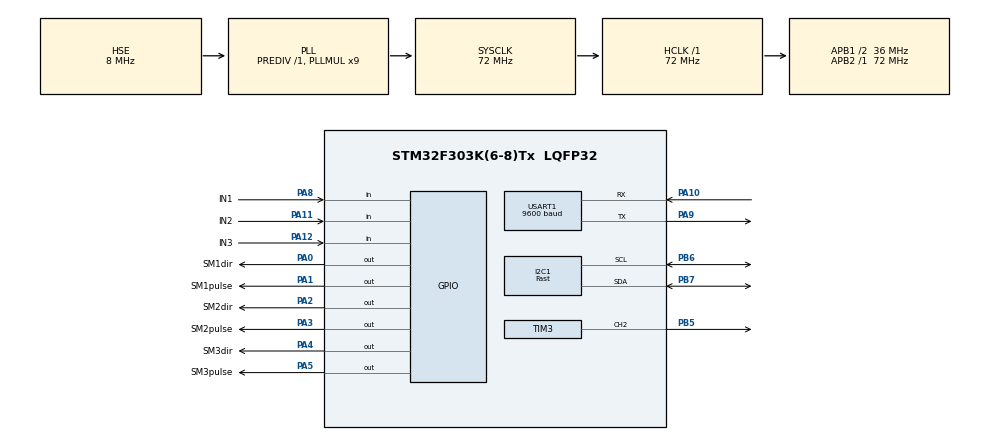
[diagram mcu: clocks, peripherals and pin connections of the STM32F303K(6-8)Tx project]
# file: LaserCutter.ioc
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Dma.I2C1_RX.1.Direction=DMA_PERIPH_TO_MEMORY
Dma.I2C1_RX.1.Instance=DMA1_Channel7
Dma.I2C1_RX.1.MemDataAlignment=DMA_MDATAALIGN_BYTE
Dma.I2C1_RX.1.MemInc=DMA_MINC_ENABLE
Dma.I2C1_RX.1.Mode=DMA_NORMAL
Dma.I2C1_RX.1.PeriphDataAlignment=DMA_PDATAALIGN_BYTE
Dma.I2C1_RX.1.PeriphInc=DMA_PINC_DISABLE
Dma.I2C1_RX.1.Priority=DMA_PRIORITY_LOW
Dma.I2C1_TX.0.Direction=DMA_MEMORY_TO_PERIPH
Dma.I2C1_TX.0.Instance=DMA1_Channel6
Dma.I2C1_TX.0.MemDataAlignment=DMA_MDATAALIGN_BYTE
Dma.I2C1_TX.0.MemInc=DMA_MINC_ENABLE
Dma.I2C1_TX.0.Mode=DMA_NORMAL
Dma.I2C1_TX.0.PeriphDataAlignment=DMA_PDATAALIGN_BYTE
Dma.I2C1_TX.0.PeriphInc=DMA_PINC_DISABLE
Dma.I2C1_TX.0.Priority=DMA_PRIORITY_LOW
Dma.Request0=I2C1_TX
Dma.Request1=I2C1_RX
Dma.Request2=USART1_RX
Dma.Request3=USART1_TX
Dma.USART1_RX.2.Direction=DMA_PERIPH_TO_MEMORY
Dma.USART1_RX.2.Instance=DMA1_Channel5
Dma.USART1_RX.2.MemDataAlignment=DMA_MDATAALIGN_BYTE
Dma.USART1_RX.2.MemInc=DMA_MINC_ENABLE
Dma.USART1_RX.2.Mode=DMA_CIRCULAR
Dma.USART1_RX.2.PeriphDataAlignment=DMA_PDATAALIGN_BYTE
Dma.USART1_RX.2.PeriphInc=DMA_PINC_DISABLE
Dma.USART1_RX.2.Priority=DMA_PRIORITY_LOW
Dma.USART1_TX.3.Direction=DMA_MEMORY_TO_PERIPH
Dma.USART1_TX.3.Instance=DMA1_Channel4
Dma.USART1_TX.3.MemDataAlignment=DMA_MDATAALIGN_BYTE
Dma.USART1_TX.3.MemInc=DMA_MINC_ENABLE
Dma.USART1_TX.3.Mode=DMA_NORMAL
Dma.USART1_TX.3.PeriphDataAlignment=DMA_PDATAALIGN_BYTE
Dma.USART1_TX.3.PeriphInc=DMA_PINC_DISABLE
Dma.USART1_TX.3.Priority=DMA_PRIORITY_LOW
I2C1.I2C_Speed_Mode=I2C_Fast
I2C1.Speed=100
I2C1.Timing=0x20000215
Mcu.Family=STM32F3
Mcu.Name=STM32F303K(6-8)Tx
Mcu.Package=LQFP32
NVIC.DMA1_Channel4_IRQn=true\:0\:0\:false\:false\:true\:false\:true
NVIC.DMA1_Channel5_IRQn=true\:0\:0\:false\:false\:true\:false\:true
NVIC.DMA1_Channel6_IRQn=true\:0\:0\:false\:false\:true\:false\:true
NVIC.DMA1_Channel7_IRQn=true\:0\:0\:false\:false\:true\:false\:true
NVIC.I2C1_EV_IRQn=true\:0\:0\:false\:false\:true\:true\:true
NVIC.PriorityGroup=NVIC_PRIORITYGROUP_4
NVIC.TIM1_TRG_COM_TIM17_IRQn=true\:0\:0\:false\:false\:true\:true\:true
NVIC.TIM1_UP_TIM16_IRQn=true\:0\:0\:false\:false\:true\:true\:true
NVIC.USART1_IRQn=true\:0\:0\:false\:false\:true\:true\:true
PA0.GPIO_Label=SM1dir
PA0.Signal=GPIO_Output
PA1.GPIO_Label=SM1pulse
PA1.Signal=GPIO_Output
PA10.Mode=Asynchronous
PA10.Signal=USART1_RX
PA11.GPIO_Label=IN2
PA11.GPIO_PuPd=GPIO_PULLUP
PA11.Signal=GPIO_Input
PA12.GPIO_Label=IN3
PA12.GPIO_PuPd=GPIO_PULLUP
PA12.Signal=GPIO_Input
PA13.Mode=Serial_Wire
PA13.Signal=SYS_JTMS-SWDIO
PA14.Mode=Serial_Wire
PA14.Signal=SYS_JTCK-SWCLK
PA2.GPIO_Label=SM2dir
PA2.Signal=GPIO_Output
PA3.GPIO_Label=SM2pulse
PA3.Signal=GPIO_Output
PA4.GPIO_Label=SM3dir
PA4.Signal=GPIO_Output
PA5.GPIO_Label=SM3pulse
PA5.Signal=GPIO_Output
PA8.GPIO_Label=IN1
PA8.GPIO_PuPd=GPIO_PULLUP
PA8.Signal=GPIO_Input
PA9.Mode=Asynchronous
PA9.Signal=USART1_TX
PB5.Signal=S_TIM3_CH2
PB6.Mode=I2C
PB6.Signal=I2C1_SCL
PB7.Mode=I2C
PB7.Signal=I2C1_SDA
PF0\ /\ OSC_IN.Mode=HSE-External-Oscillator
PF0\ /\ OSC_IN.Signal=RCC_OSC_IN
PF1\ /\ OSC_OUT.Mode=HSE-External-Oscillator
PF1\ /\ OSC_OUT.Signal=RCC_OSC_OUT
ProjectManager.HeapSize=0x200
ProjectManager.StackSize=0x400
ProjectManager.TargetToolchain=STM32CubeIDE
RCC.AHBFreq_Value=72000000
RCC.APB1CLKDivider=RCC_HCLK_DIV2
RCC.APB1Freq_Value=36000000
RCC.APB1TimFreq_Value=72000000
RCC.APB2Freq_Value=72000000
RCC.APB2TimFreq_Value=72000000
RCC.CortexFreq_Value=72000000
RCC.HCLKFreq_Value=72000000
RCC.HSE_VALUE=8000000
RCC.HSI_VALUE=8000000
RCC.PLLMUL=RCC_PLL_MUL9
RCC.PLLSourceVirtual=RCC_PLLSOURCE_HSE
RCC.SYSCLKFreq_VALUE=72000000
RCC.SYSCLKSourceVirtual=RCC_SYSCLKSOURCE_PLLCLK
SH.S_TIM3_CH2.0=TIM3_CH2,PWM Generation2 CH2
TIM16.Period=7199
TIM16.Prescaler=9
TIM17.Period=7199
TIM17.Prescaler=999
TIM3.Channel-PWM\ Generation2\ CH2=TIM_CHANNEL_2
TIM3.Period=999
TIM3.Prescaler=35
USART1.BaudRate=9600
USART1.SwapParam=ADVFEATURE_SWAP_ENABLE
USART1.VirtualMode-Asynchronous=VM_ASYNC
VP_TIM16_VS_ClockSourceINT.Mode=Enable_Timer
VP_TIM17_VS_ClockSourceINT.Mode=Enable_Timer
board=custom

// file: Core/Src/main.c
/* USER CODE BEGIN Header */
/**
  ******************************************************************************
  * @file           : main.c
  * @brief          : Main program body
  ******************************************************************************
  * @attention
  *
  * <h2><center>&copy; Copyright (c) 2020 STMicroelectronics.
  * All rights reserved.</center></h2>
  *
  * This software component is licensed by ST under BSD 3-Clause license,
  * the "License"; You may not use this file except in compliance with the
  * License. You may obtain a copy of the License at:
  *                        opensource.org/licenses/BSD-3-Clause
  *
  ******************************************************************************
  */
/* USER CODE END Header */

#include "main.h"
#include "dma.h"
#include "i2c.h"
#include "tim.h"
#include "usart.h"
#include "gpio.h"

/* USER CODE BEGIN Includes */
#include "my_func.h"
/* USER CODE END Includes */

void SystemClock_Config(void);

int main(void)
{

  /* MCU Configuration--------------------------------------------------------*/

  /* Reset of all peripherals, Initializes the Flash interface and the Systick. */
  HAL_Init();

  /* Configure the system clock */
  SystemClock_Config();

  /* Initialize all configured peripherals */
  MX_GPIO_Init();
  MX_DMA_Init();
  MX_I2C1_Init();
  MX_USART1_UART_Init();
  MX_TIM16_Init();
  MX_TIM17_Init();
  MX_TIM3_Init();
  /* USER CODE BEGIN 2 */
  Init();
  /* USER CODE END 2 */

  /* Infinite loop */
  while (1)
  {

    /* USER CODE BEGIN 3 */
	  Loop();
  }
  /* USER CODE END 3 */
}

void SystemClock_Config(void)
{
  RCC_OscInitTypeDef RCC_OscInitStruct = {0};
  RCC_ClkInitTypeDef RCC_ClkInitStruct = {0};
  RCC_PeriphCLKInitTypeDef PeriphClkInit = {0};

  /** Initializes the CPU, AHB and APB busses clocks
  */
  RCC_OscInitStruct.OscillatorType = RCC_OSCILLATORTYPE_HSI|RCC_OSCILLATORTYPE_HSE;
  RCC_OscInitStruct.HSEState = RCC_HSE_ON;
  RCC_OscInitStruct.HSEPredivValue = RCC_HSE_PREDIV_DIV1;
  RCC_OscInitStruct.HSIState = RCC_HSI_ON;
  RCC_OscInitStruct.HSICalibrationValue = RCC_HSICALIBRATION_DEFAULT;
  RCC_OscInitStruct.PLL.PLLState = RCC_PLL_ON;
  RCC_OscInitStruct.PLL.PLLSource = RCC_PLLSOURCE_HSE;
  RCC_OscInitStruct.PLL.PLLMUL = RCC_PLL_MUL9;
  if (HAL_RCC_OscConfig(&RCC_OscInitStruct) != HAL_OK)
  {
    Error_Handler();
  }
  /** Initializes the CPU, AHB and APB busses clocks
  */
  RCC_ClkInitStruct.ClockType = RCC_CLOCKTYPE_HCLK|RCC_CLOCKTYPE_SYSCLK
                              |RCC_CLOCKTYPE_PCLK1|RCC_CLOCKTYPE_PCLK2;
  RCC_ClkInitStruct.SYSCLKSource = RCC_SYSCLKSOURCE_PLLCLK;
  RCC_ClkInitStruct.AHBCLKDivider = RCC_SYSCLK_DIV1;
  RCC_ClkInitStruct.APB1CLKDivider = RCC_HCLK_DIV2;
  RCC_ClkInitStruct.APB2CLKDivider = RCC_HCLK_DIV1;

  if (HAL_RCC_ClockConfig(&RCC_ClkInitStruct, FLASH_LATENCY_2) != HAL_OK)
  {
    Error_Handler();
  }
  PeriphClkInit.PeriphClockSelection = RCC_PERIPHCLK_USART1|RCC_PERIPHCLK_I2C1;
  PeriphClkInit.Usart1ClockSelection = RCC_USART1CLKSOURCE_PCLK1;
  PeriphClkInit.I2c1ClockSelection = RCC_I2C1CLKSOURCE_HSI;
  if (HAL_RCCEx_PeriphCLKConfig(&PeriphClkInit) != HAL_OK)
  {
    Error_Handler();
  }
}

/* USER CODE BEGIN 4 */
#if __cplusplus
};
#endif
/* USER CODE END 4 */

void Error_Handler(void)
{
}

/************************ (C) COPYRIGHT STMicroelectronics *****END OF FILE****/
